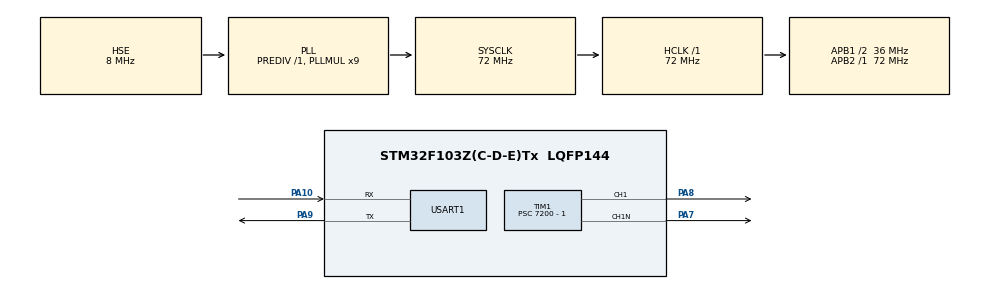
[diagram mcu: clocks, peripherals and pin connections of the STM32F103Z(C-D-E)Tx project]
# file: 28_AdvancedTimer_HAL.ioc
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Mcu.Family=STM32F1
Mcu.Name=STM32F103Z(C-D-E)Tx
Mcu.Package=LQFP144
NVIC.PriorityGroup=NVIC_PRIORITYGROUP_4
NVIC.TIM1_UP_IRQn=true\:0\:0\:false\:false\:true\:true\:true\:true
OSC_IN.Mode=HSE-External-Oscillator
OSC_IN.Signal=RCC_OSC_IN
OSC_OUT.Mode=HSE-External-Oscillator
OSC_OUT.Signal=RCC_OSC_OUT
PA10.Mode=Asynchronous
PA10.Signal=USART1_RX
PA13.Mode=Serial_Wire
PA13.Signal=SYS_JTMS-SWDIO
PA14.Mode=Serial_Wire
PA14.Signal=SYS_JTCK-SWCLK
PA7.Mode=PWM Generation1 CH1 CH1N
PA7.Signal=TIM1_CH1N
PA8.Signal=S_TIM1_CH1
PA9.Mode=Asynchronous
PA9.Signal=USART1_TX
PC14-OSC32_IN.Mode=LSE-External-Oscillator
PC14-OSC32_IN.Signal=RCC_OSC32_IN
PC15-OSC32_OUT.Mode=LSE-External-Oscillator
PC15-OSC32_OUT.Signal=RCC_OSC32_OUT
ProjectManager.HeapSize=0x200
ProjectManager.StackSize=0x400
ProjectManager.TargetToolchain=MDK-ARM V5.32
RCC.AHBFreq_Value=72000000
RCC.APB1CLKDivider=RCC_HCLK_DIV2
RCC.APB1Freq_Value=36000000
RCC.APB1TimFreq_Value=72000000
RCC.APB2Freq_Value=72000000
RCC.APB2TimFreq_Value=72000000
RCC.HCLKFreq_Value=72000000
RCC.PLLMUL=RCC_PLL_MUL9
RCC.PLLSourceVirtual=RCC_PLLSOURCE_HSE
RCC.SYSCLKFreq_VALUE=72000000
RCC.SYSCLKSource=RCC_SYSCLKSOURCE_PLLCLK
RCC.USBFreq_Value=72000000
SH.S_TIM1_CH1.0=TIM1_CH1,PWM Generation1 CH1 CH1N
TIM1.Channel-PWM\ Generation1\ CH1\ CH1N=TIM_CHANNEL_1
TIM1.OCFastMode_PWM-PWM\ Generation1\ CH1\ CH1N=TIM_OCFAST_ENABLE
TIM1.Period=5000 - 1
TIM1.Prescaler=7200 - 1
TIM1.Pulse-PWM\ Generation1\ CH1\ CH1N=2500
TIM1.RepetitionCounter=5 - 1
USART1.VirtualMode=VM_ASYNC
VP_TIM1_VS_ClockSourceINT.Mode=Internal
board=custom

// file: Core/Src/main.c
/* USER CODE BEGIN Header */
/**
  ******************************************************************************
  * @file           : main.c
  * @brief          : Main program body
  ******************************************************************************
  * @attention
  *
  * Copyright (c) 2024 STMicroelectronics.
  * All rights reserved.
  *
  * This software is licensed under terms that can be found in the LICENSE file
  * in the root directory of this software component.
  * If no LICENSE file comes with this software, it is provided AS-IS.
  *
  ******************************************************************************
  */
/* USER CODE END Header */
#include "main.h"
#include "tim.h"
#include "usart.h"
#include "gpio.h"

void SystemClock_Config(void);

int main(void)
{

  /* MCU Configuration--------------------------------------------------------*/

  /* Reset of all peripherals, Initializes the Flash interface and the Systick. */
  HAL_Init();

  /* Configure the system clock */
  SystemClock_Config();

  /* Initialize all configured peripherals */
  MX_GPIO_Init();
  MX_TIM1_Init();
  MX_USART1_UART_Init();

  /* Infinite loop */
  /* USER CODE BEGIN WHILE */

  /* 防止一启动就进入中断，在MX_TIM1_Init()中已经触发更新事件引发更新中断，只需要手动清除中断标志位
  Generate an update event to reload the Prescaler and the repetition counter (only for advanced timer) value immediately

  TIMx->EGR = TIM_EGR_UG; 这个操作会将中断标志位置为1，既是没有Enable更新中断

  手动清除中断标志位
  */
  __HAL_TIM_CLEAR_FLAG(&htim1, TIM_FLAG_UPDATE);

  /* 因为HAL_TIM_PWM_Start_IT中并没有启用更新中断，因此要开启更新中断，如果没有清除中断标志位，在启动更新中断后会立刻进入中断 */
  /* 方式1 */
  // HAL_TIM_Base_Start_IT(&htim1);
  /* 方式2 */
  __HAL_TIM_ENABLE_IT(&htim1, TIM_IT_UPDATE);

  /* 开启定时器1的PWM */
  // HAL_TIM_PWM_Start_IT(&htim1, TIM_CHANNEL_1);
  /* 因为上面这个函数中开启的只是捕获/比较中断，目前用不到，可以直接使用下面这个 */
  HAL_TIM_PWM_Start(&htim1, TIM_CHANNEL_1);

  while (1)
  {
    /* USER CODE END WHILE */

  }
}

void SystemClock_Config(void)
{
  RCC_OscInitTypeDef RCC_OscInitStruct = {0};
  RCC_ClkInitTypeDef RCC_ClkInitStruct = {0};

  /** Initializes the RCC Oscillators according to the specified parameters
  * in the RCC_OscInitTypeDef structure.
  */
  RCC_OscInitStruct.OscillatorType = RCC_OSCILLATORTYPE_HSE;
  RCC_OscInitStruct.HSEState = RCC_HSE_ON;
  RCC_OscInitStruct.HSEPredivValue = RCC_HSE_PREDIV_DIV1;
  RCC_OscInitStruct.HSIState = RCC_HSI_ON;
  RCC_OscInitStruct.PLL.PLLState = RCC_PLL_ON;
  RCC_OscInitStruct.PLL.PLLSource = RCC_PLLSOURCE_HSE;
  RCC_OscInitStruct.PLL.PLLMUL = RCC_PLL_MUL9;
  if (HAL_RCC_OscConfig(&RCC_OscInitStruct) != HAL_OK)
  {
    Error_Handler();
  }

  /** Initializes the CPU, AHB and APB buses clocks
  */
  RCC_ClkInitStruct.ClockType = RCC_CLOCKTYPE_HCLK|RCC_CLOCKTYPE_SYSCLK
                              |RCC_CLOCKTYPE_PCLK1|RCC_CLOCKTYPE_PCLK2;
  RCC_ClkInitStruct.SYSCLKSource = RCC_SYSCLKSOURCE_PLLCLK;
  RCC_ClkInitStruct.AHBCLKDivider = RCC_SYSCLK_DIV1;
  RCC_ClkInitStruct.APB1CLKDivider = RCC_HCLK_DIV2;
  RCC_ClkInitStruct.APB2CLKDivider = RCC_HCLK_DIV1;

  if (HAL_RCC_ClockConfig(&RCC_ClkInitStruct, FLASH_LATENCY_2) != HAL_OK)
  {
    Error_Handler();
  }
}

void Error_Handler(void)
{
  __disable_irq();
  while (1)
  {
  }
}
